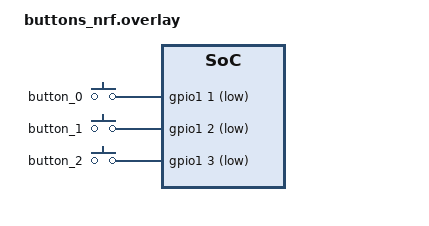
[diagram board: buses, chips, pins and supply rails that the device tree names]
/*
 * Buttons nRF — Remappr shield (generated by remappr).
 *
 * Drop this directory into a remappr-firmware checkout under
 * boards/shields/buttons_nrf/ and build with -D<app>_SHIELD=buttons_nrf. Verify the
 * row/col GPIO specs against your wiring — remappr derives the matrix
 * cells from physical key position, not the electrical matrix.
 *
 * SPDX-License-Identifier: Apache-2.0
 */

#include <zephyr/dt-bindings/input/input-event-codes.h>
#include <zephyr/dt-bindings/input/keymap.h>
#include <dt-bindings/remappr/keys.h>
#include <dt-bindings/remappr/layout.h>
#include <remappr/keymap-tokens.dtsi>
#include <remappr/behavior-tokens.dtsi>

/ {
	remappr_keymap: remappr-keymap {
		compatible = "remappr,keymap";
		extra-input-codes = <INPUT_KEY_F13 INPUT_KEY_F14 INPUT_KEY_ENTER>;
		columns = <3>;
		rows = <3>;
		max-layers = <4>;
		placement = <
				KEY(&x 0 &y 0) KEY(&x 1 &y 0) KEY(&x 2 &y 0 &w 2)
		>;
		layer_0 {
			compatible = "remappr,keymap-layer";
			index = <0>;
			actions = <
				&key 0x04 &key 0x05 &key 0x28
			>;
		};
		layer_1 {
			compatible = "remappr,keymap-layer";
			index = <1>;
			actions = <
				&key 0x1E &key 0x1F &key 0x20
			>;
		};
	};
};

/ {
	remappr_buttons {
		compatible = "gpio-keys";
		button_0 {
			gpios = <&gpio1 1 (GPIO_ACTIVE_LOW | GPIO_PULL_UP)>;
			zephyr,code = <INPUT_KEY_F13>;
		};
		button_1 {
			gpios = <&gpio1 2 (GPIO_ACTIVE_LOW | GPIO_PULL_UP)>;
			zephyr,code = <INPUT_KEY_F14>;
		};
		button_2 {
			gpios = <&gpio1 3 (GPIO_ACTIVE_LOW | GPIO_PULL_UP)>;
			zephyr,code = <INPUT_KEY_ENTER>;
		};
	};
};
